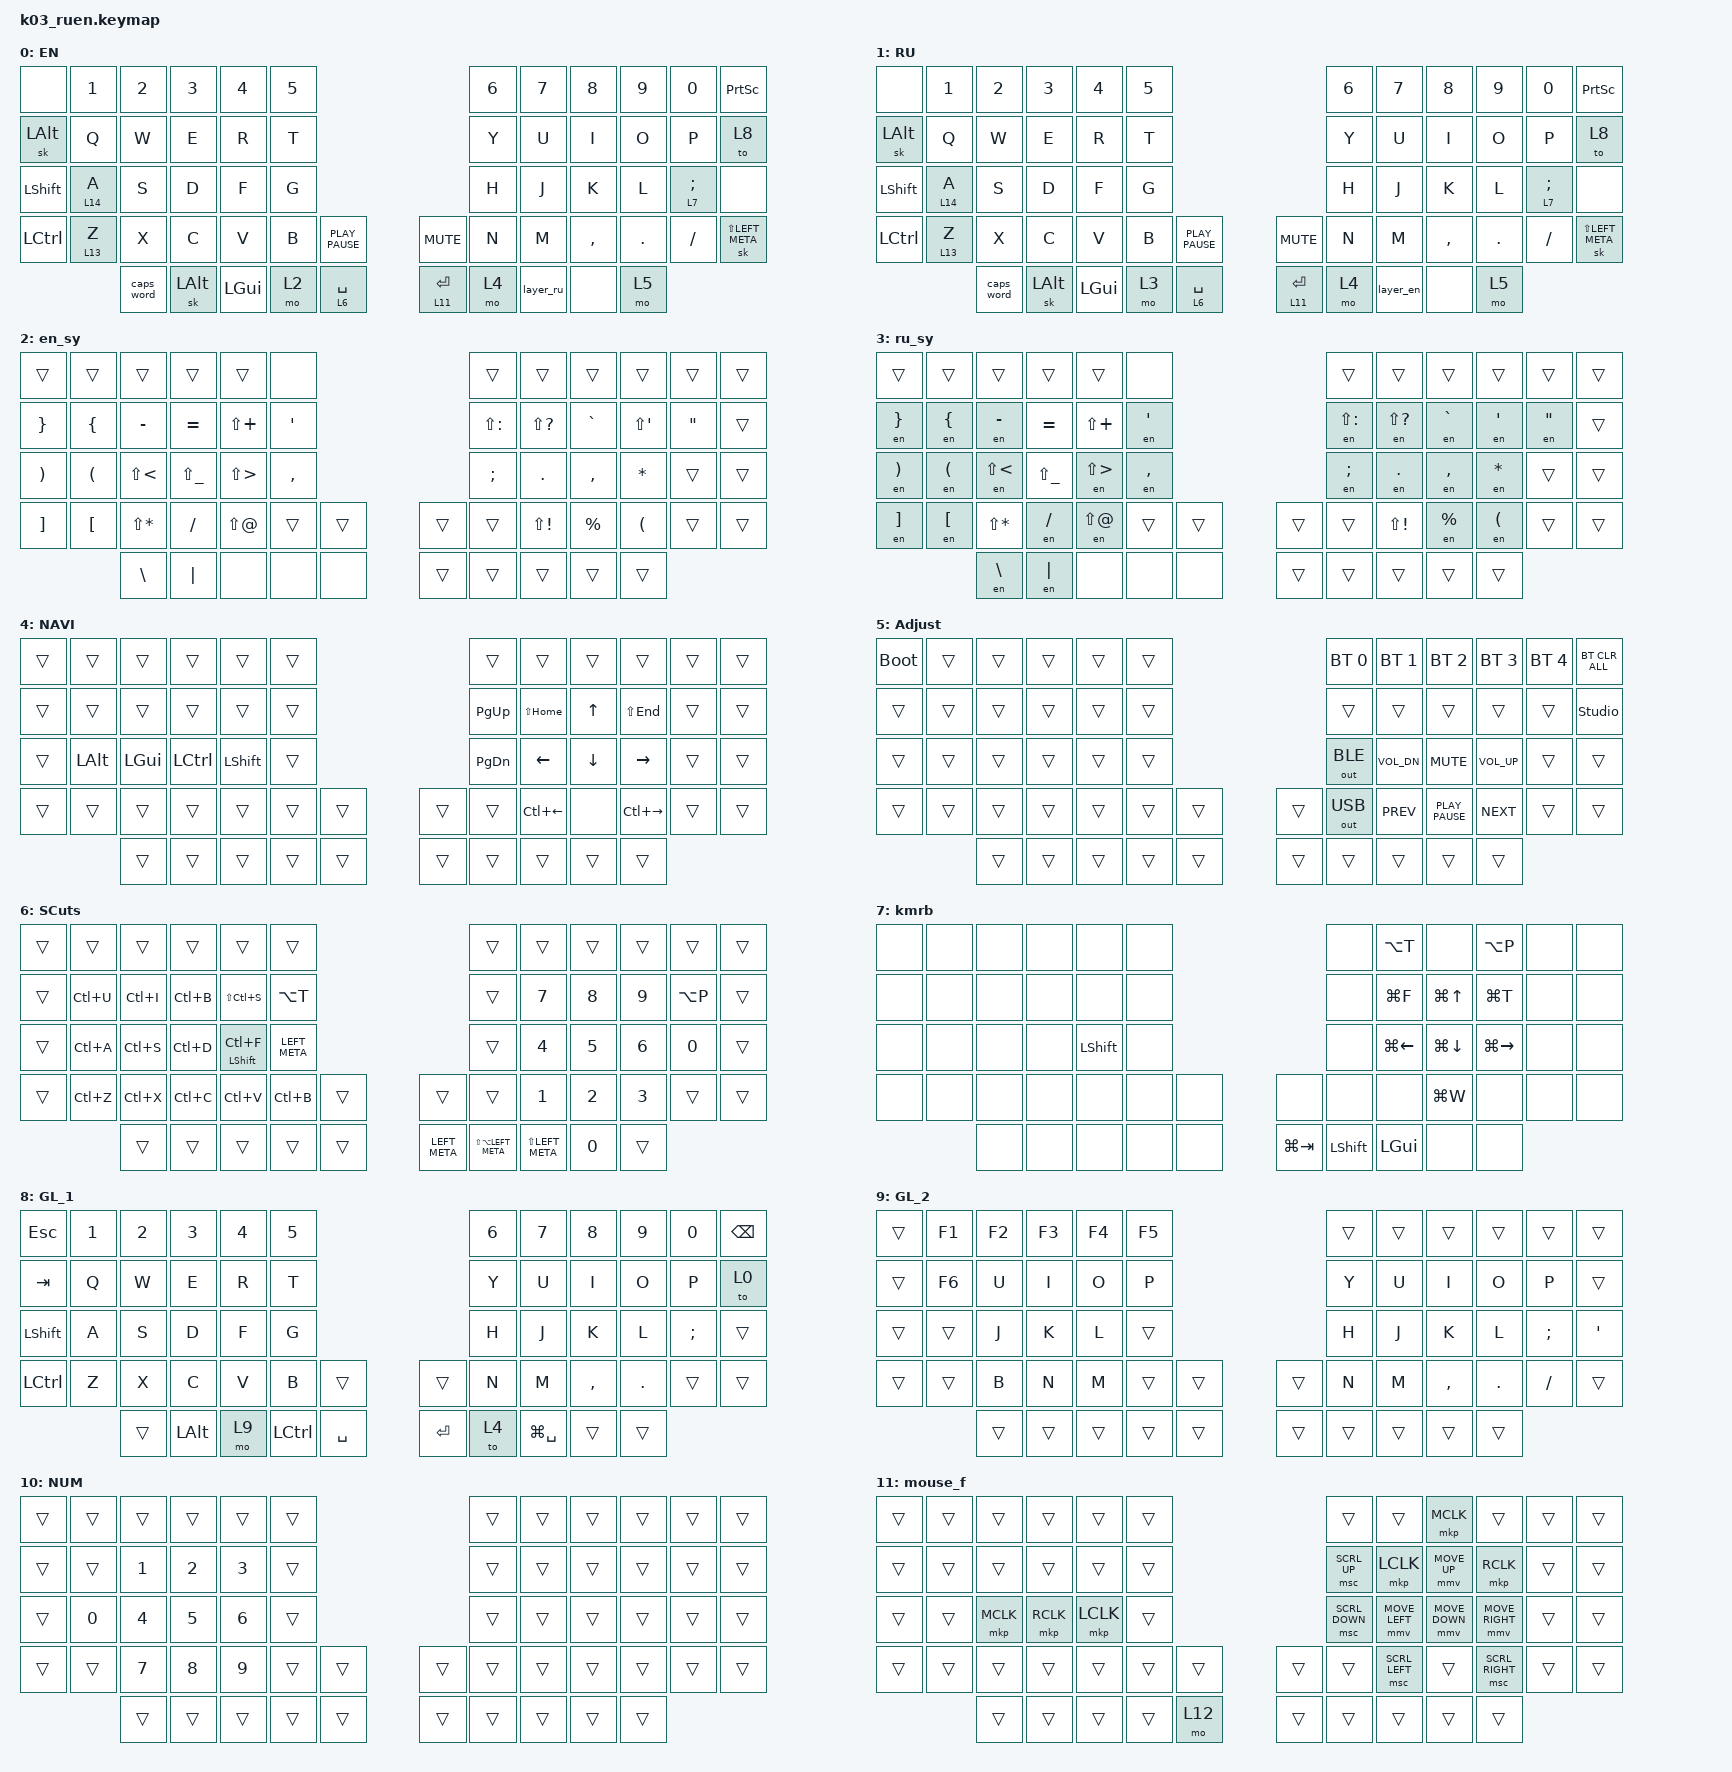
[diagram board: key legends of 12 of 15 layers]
#define ZMK_POINTING_DEFAULT_MOVE_VAL 1200
#define ZMK_POINTING_DEFAULT_SCRL_VAL 20

#include "keys_ru.h"
#include <input/processors.dtsi>
#include <behaviors.dtsi>
#include <dt-bindings/zmk/bt.h>
#include <dt-bindings/zmk/keys.h>
#include <dt-bindings/zmk/outputs.h>
#include <dt-bindings/zmk/pointing.h>

&mmv {
    time-to-max-speed-ms = <150>;
    acceleration-exponent = <1>;
};

&lt { tapping-term-ms = <185>; };

&mmv_input_listener {
    sniper {
        input-processors = <&zip_xy_scaler 1 6>;
        layers = <12>;
    };
};

/ {
    behaviors {
        enc_vol: enc_vol {
            compatible = "zmk,behavior-sensor-rotate";
            label = "ENC_VOL";
            #sensor-binding-cells = <0>;
            bindings = <&kp C_VOL_UP>, <&kp C_VOL_DN>;
        };

        td0: td0 {
            compatible = "zmk,behavior-tap-dance";
            label = "TD0";
            #binding-cells = <0>;
            bindings = <&kp MINUS>, <&kp LC(SLASH)>;

            tapping-term-ms = <300>;
        };

        td2: td2 {
            compatible = "zmk,behavior-tap-dance";
            label = "TD2";
            #binding-cells = <0>;
            tapping-term-ms = <300>;
            bindings = <&kp LS(LA(LEFT_BRACKET))>, <&kp LS(LA(H))>;
        };

        td3: td3 {
            compatible = "zmk,behavior-tap-dance";
            label = "TD3";
            #binding-cells = <0>;
            bindings = <&kp LS(LA(RIGHT_BRACKET))>, <&kp LS(LA(L))>;

            tapping-term-ms = <300>;
        };

        td4: td4 {
            compatible = "zmk,behavior-tap-dance";
            label = "TD4";
            #binding-cells = <0>;
            bindings = <&kp MINUS>, <&kp LC(SLASH)>;

            tapping-term-ms = <300>;
        };

        screen_shot: screen_shot {
            compatible = "zmk,behavior-tap-dance";
            label = "SCREEN_SHOT";
            #binding-cells = <0>;
            bindings = <&kp LS(PRINTSCREEN)>, <&kp PRINTSCREEN>;

            tapping-term-ms = <300>;
        };

        l_tap_hold: l_tap_hold {
            compatible = "zmk,behavior-hold-tap";
            label = "L_TAP_HOLD";
            bindings = <&mo>, <&kp>;

            #binding-cells = <2>;
            tapping-term-ms = <175>;
        };

        copy_paste_tap_dance: copy_paste_tap_dance {
            compatible = "zmk,behavior-hold-tap";
            label = "COPY_PASTE_TAP_DANCE";
            bindings = <&kp>, <&kp>;

            #binding-cells = <2>;
            flavor = "tap-preferred";
            tapping-term-ms = <190>;
            hold-trigger-on-release;
        };

        hrm: hrm {
            compatible = "zmk,behavior-hold-tap";
            label = "HRM";
            bindings = <&kp>, <&kp>;

            #binding-cells = <2>;
            tapping-term-ms = <190>;
            flavor = "tap-preferred";
        };
    };

    combos {
        compatible = "zmk,combos";

        ent {
            bindings = <&kp ENTER>;
            key-positions = <31 32>;
            layers = <4 8>;
        };

        bspac {
            bindings = <&kp BACKSPACE>;
            key-positions = <32 33>;
            layers = <4 8>;
        };

        del {
            bindings = <&kp DELETE>;
            key-positions = <46 47>;
            layers = <4>;
        };

        all {
            bindings = <&kp LC(A)>;
            key-positions = <25 26>;
            layers = <2 3>;
        };

        x {
            bindings = <&kp LEFT_BRACKET>;
            key-positions = <40 41>;
            layers = <0 1>;
        };

        left_br {
            bindings = <&kp RIGHT_BRACKET>;
            key-positions = <44 45>;
            layers = <0 1>;
        };

        e {
            bindings = <&kp SQT>;
            key-positions = <20 21>;
            layers = <0 1>;
        };

        esc {
            bindings = <&kp ESC>;
            key-positions = <13 14>;
            layers = <0 1>;
        };

        ctrT {
            bindings = <&kp LC(T)>;
            key-positions = <17 16>;
            layers = <2 3>;
        };

        buffer {
            bindings = <&kp LC(LG(V))>;
            key-positions = <39 40>;
            layers = <2 3>;
        };

        compact {
            bindings = <&kp LA(LC(C))>;
            key-positions = <37 38>;
            layers = <2 3>;
        };

        left_enter {
            bindings = <&kp ENTER>;
            key-positions = <28 27>;
            layers = <2 3>;
        };

        left_backspace {
            bindings = <&kp BACKSPACE>;
            key-positions = <27 26>;
            layers = <2 3>;
        };

        left_del {
            bindings = <&kp DELETE>;
            key-positions = <38 39>;
            layers = <2 3>;
        };

        tab {
            bindings = <&kp TAB>;
            key-positions = <15 14>;
            layers = <0 1>;
        };

        caps_work {
            bindings = <&caps_word>;
            key-positions = <26 28>;
            layers = <0 1>;
        };

        tg_swtcher {
            bindings = <&tog 13>;
            key-positions = <24 25>;
            layers = <0 1 13>;
        };
    };

    macros {
        to_ru: to_ru {
            compatible = "zmk,behavior-macro";
            #binding-cells = <0>;
            bindings = <&kp LS(LC(NUMBER_8))>;
            label = "TO_RU";
            wait-ms = <0>;
            tap-ms = <30>;
        };

        to_en: to_en {
            compatible = "zmk,behavior-macro";
            #binding-cells = <0>;
            bindings = <&kp LS(LC(N9))>;
            label = "TO_EN";
            wait-ms = <0>;
            tap-ms = <30>;
        };

        layer_en: layer_en {
            compatible = "zmk,behavior-macro";
            #binding-cells = <0>;
            bindings = <&to 0 &to_en>;
            label = "LAYER_EN";
            wait-ms = <0>;
            tap-ms = <30>;
        };

        layer_ru: layer_ru {
            compatible = "zmk,behavior-macro";
            #binding-cells = <0>;
            bindings = <&to 1 &to_ru>;
            label = "LAYER_RU";
            tap-ms = <30>;
            wait-ms = <0>;
        };

        en: en {
            compatible = "zmk,behavior-macro-one-param";
            #binding-cells = <1>;
            bindings =
                <&to_en>,
                <&macro_press>,
                <&macro_param_1to1 &kp MACRO_PLACEHOLDER>,
                <&macro_pause_for_release>,
                <&macro_release>,
                <&macro_param_1to1 &kp MACRO_PLACEHOLDER>,
                <&macro_tap>,
                <&to_ru>;

            label = "EN";
            wait-ms = <0>;
            tap-ms = <30>;
        };
    };

    keymap {
        compatible = "zmk,keymap";

        EN {
            bindings = <
&none         &kp N1    &kp N2      &kp N3        &kp N4        &kp N5                                       &kp N6  &kp N7     &kp N8     &kp N9   &kp N0      &kp PRINTSCREEN
&sk LEFT_ALT  &kp Q     &kp W       &kp E         &kp R         &kp T                                        &kp Y   &kp U      &kp I      &kp O    &kp P       &to 8
&kp LSHFT     &lt 14 A  &kp S       &kp D         &kp F         &kp G                                        &kp H   &kp J      &kp K      &kp L    &lt 7 SEMI  &none
&kp LCTRL     &lt 13 Z  &kp X       &kp C         &kp V         &kp B   &kp K_PLAY_PAUSE       &kp C_MUTE    &kp N   &kp M      &kp COMMA  &kp DOT  &kp FSLH    &sk LS(LEFT_META)
                        &caps_word  &sk LEFT_ALT  &kp LEFT_GUI  &mo 2   &l_tap_hold 6 SPACE    &lt 11 ENTER  &mo 4   &layer_ru  &none      &mo 5
            >;

            display-name = "EN";
            sensor-bindings = <&inc_dec_kp K_NEXT K_PREV>, <&enc_vol>;

            label = "EN";
        };

        RU {
            label = "RU";
            display-name = "RU";
            bindings = <
&none         &kp N1    &kp N2      &kp N3        &kp N4        &kp N5                                       &kp N6  &kp N7     &kp N8     &kp N9   &kp N0      &kp PRINTSCREEN
&sk LEFT_ALT  &kp Q     &kp W       &kp E         &kp R         &kp T                                        &kp Y   &kp U      &kp I      &kp O    &kp P       &to 8
&kp LSHFT     &lt 14 A  &kp S       &kp D         &kp F         &kp G                                        &kp H   &kp J      &kp K      &kp L    &lt 7 SEMI  &none
&kp LCTRL     &lt 13 Z  &kp X       &kp C         &kp V         &kp B   &kp K_PLAY_PAUSE       &kp C_MUTE    &kp N   &kp M      &kp COMMA  &kp DOT  &kp FSLH    &sk LS(LEFT_META)
                        &caps_word  &sk LEFT_ALT  &kp LEFT_GUI  &mo 3   &l_tap_hold 6 SPACE    &lt 11 ENTER  &mo 4   &layer_en  &none      &mo 5
            >;

            sensor-bindings = <&inc_dec_kp K_NEXT K_PREV>, <&enc_vol>;
        };

        en_sy {
            bindings = <
&trans                 &trans                &trans         &trans         &trans        &none                        &trans         &trans         &trans     &trans                &trans   &trans
&kp RIGHT_BRACE        &kp LEFT_BRACE        &kp MINUS      &kp EQUAL      &kp LS(PLUS)  &kp SQT                      &kp LS(COLON)  &kp LS(QMARK)  &kp GRAVE  &kp LS(SQT)           &kp DQT  &trans
&kp RIGHT_PARENTHESIS  &kp LEFT_PARENTHESIS  &kp LS(LT)     &kp LS(UNDER)  &kp LS(GT)    &kp COMMA                    &kp SEMI       &kp DOT        &kp COMMA  &kp STAR              &trans   &trans
&kp RIGHT_BRACKET      &kp LEFT_BRACKET      &kp LS(STAR)   &kp FSLH       &kp LS(AT)    &trans     &trans    &trans  &trans         &kp LS(EXCL)   &kp PRCNT  &kp LEFT_PARENTHESIS  &trans   &trans
                                             &kp BACKSLASH  &kp PIPE       &none         &none      &none     &trans  &trans         &trans         &trans     &trans
            >;

            label = "en_sy";
        };

        ru_sy {
            bindings = <
&trans                 &trans            &trans         &trans         &trans        &none                        &trans         &trans         &trans     &trans                &trans   &trans
&en RIGHT_BRACE        &en LEFT_BRACE    &en MINUS      &kp EQUAL      &kp LS(PLUS)  &en SQT                      &en LS(COLON)  &en LS(QMARK)  &en GRAVE  &en SQT               &en DQT  &trans
&en RIGHT_PARENTHESIS  &en LPAR          &en LS(LT)     &kp LS(UNDER)  &en LS(GT)    &en COMMA                    &en SEMI       &en DOT        &en COMMA  &en STAR              &trans   &trans
&en RIGHT_BRACKET      &en LEFT_BRACKET  &kp LS(STAR)   &en FSLH       &en LS(AT)    &trans     &trans    &trans  &trans         &kp LS(EXCL)   &en PRCNT  &en LEFT_PARENTHESIS  &trans   &trans
                                         &en BACKSLASH  &en PIPE       &none         &none      &none     &trans  &trans         &trans         &trans     &trans
            >;

            label = "ru_sy";
        };

        NAVI {
            bindings = <
&trans  &trans    &trans    &trans            &trans          &trans                    &trans     &trans        &trans    &trans         &trans  &trans
&trans  &trans    &trans    &trans            &trans          &trans                    &kp PG_UP  &kp LS(HOME)  &kp UP    &kp LS(END)    &trans  &trans
&trans  &kp LALT  &kp LGUI  &kp LEFT_CONTROL  &kp LEFT_SHIFT  &trans                    &kp PG_DN  &kp LEFT      &kp DOWN  &kp RIGHT      &trans  &trans
&trans  &trans    &trans    &trans            &trans          &trans  &trans    &trans  &trans     &kp LC(LEFT)  &none     &kp LC(RIGHT)  &trans  &trans
                  &trans    &trans            &trans          &trans  &trans    &trans  &trans     &trans        &trans    &trans
            >;

            label = "NAVI";
        };

        adj {
            bindings = <
&bootloader  &trans  &trans  &trans  &trans  &trans                    &bt BT_SEL 0  &bt BT_SEL 1  &bt BT_SEL 2      &bt BT_SEL 3  &bt BT_SEL 4  &bt BT_CLR_ALL
&trans       &trans  &trans  &trans  &trans  &trans                    &trans        &trans        &trans            &trans        &trans        &studio_unlock
&trans       &trans  &trans  &trans  &trans  &trans                    &out OUT_BLE  &kp C_VOL_DN  &kp K_MUTE        &kp C_VOL_UP  &trans        &trans
&trans       &trans  &trans  &trans  &trans  &trans  &trans    &trans  &out OUT_USB  &kp K_PREV    &kp K_PLAY_PAUSE  &kp K_NEXT    &trans        &trans
                     &trans  &trans  &trans  &trans  &trans    &trans  &trans        &trans        &trans            &trans
            >;

            display-name = "Adjust";
        };

        SCuts {
            bindings = <
&trans  &trans     &trans     &trans     &trans                &trans                                  &trans                 &trans             &trans  &trans  &trans     &trans
&trans  &kp LC(U)  &kp LC(I)  &kp LC(B)  &kp LS(LC(S))         &kp LA(T)                               &trans                 &kp N7             &kp N8  &kp N9  &kp LA(P)  &trans
&trans  &kp LC(A)  &kp LC(S)  &kp LC(D)  &mt LEFT_SHIFT LC(F)  &kp LEFT_META                           &trans                 &kp N4             &kp N5  &kp N6  &kp N0     &trans
&trans  &kp LC(Z)  &kp LC(X)  &kp LC(C)  &kp LC(V)             &kp LC(B)      &trans    &trans         &trans                 &kp N1             &kp N2  &kp N3  &trans     &trans
                   &trans     &trans     &trans                &trans         &trans    &kp LEFT_META  &kp LS(LA(LEFT_META))  &kp LS(LEFT_META)  &kp N0  &trans
            >;

            label = "SCuts";
        };

        kmrb {
            bindings = <
&none  &none  &none  &none  &none           &none                        &none      &kp LA(T)     &none         &kp LA(P)            &none  &none
&none  &none  &none  &none  &none           &none                        &none      &kp LG(F)     &kp LG(UP)    &kp LG(T)            &none  &none
&none  &none  &none  &none  &kp LEFT_SHIFT  &none                        &none      &kp LG(LEFT)  &kp LG(DOWN)  &kp LG(RIGHT_ARROW)  &none  &none
&none  &none  &none  &none  &none           &none  &none    &none        &none      &none         &kp LG(W)     &none                &none  &none
              &none  &none  &none           &none  &none    &kp LG(TAB)  &kp LSHFT  &kp LGUI      &none         &none
            >;

            label = "kmrb";
        };

        GL_1 {
            bindings = <
&kp ESC    &kp N1  &kp N2  &kp N3    &kp N4  &kp N5                             &kp N6  &kp N7         &kp N8     &kp N9   &kp N0    &kp BSPC
&kp TAB    &kp Q   &kp W   &kp E     &kp R   &kp T                              &kp Y   &kp U          &kp I      &kp O    &kp P     &to 0
&kp LSHFT  &kp A   &kp S   &kp D     &kp F   &kp G                              &kp H   &kp J          &kp K      &kp L    &kp SEMI  &trans
&kp LCTRL  &kp Z   &kp X   &kp C     &kp V   &kp B      &trans       &trans     &kp N   &kp M          &kp COMMA  &kp DOT  &trans    &trans
                   &trans  &kp LALT  &mo 9   &kp LCTRL  &kp SPACE    &kp ENTER  &to 4   &kp LG(SPACE)  &trans     &trans
            >;

            label = "GL_1";
            sensor-bindings = <&inc_dec_kp C_NEXT K_PREV>, <&enc_vol>;
        };

        GL_2 {
            bindings = <
&trans  &kp F1  &kp F2  &kp F3  &kp F4  &kp F5                    &trans  &trans  &trans     &trans   &trans    &trans
&trans  &kp F6  &kp U   &kp I   &kp O   &kp P                     &kp Y   &kp U   &kp I      &kp O    &kp P     &trans
&trans  &trans  &kp J   &kp K   &kp L   &trans                    &kp H   &kp J   &kp K      &kp L    &kp SEMI  &kp APOS
&trans  &trans  &kp B   &kp N   &kp M   &trans  &trans    &trans  &kp N   &kp M   &kp COMMA  &kp DOT  &kp FSLH  &trans
                &trans  &trans  &trans  &trans  &trans    &trans  &trans  &trans  &trans     &trans
            >;

            label = "GL_2";
        };

        NUM {
            bindings = <
&trans  &trans  &trans  &trans  &trans  &trans                    &trans  &trans  &trans  &trans  &trans  &trans
&trans  &trans  &kp N1  &kp N2  &kp N3  &trans                    &trans  &trans  &trans  &trans  &trans  &trans
&trans  &kp N0  &kp N4  &kp N5  &kp N6  &trans                    &trans  &trans  &trans  &trans  &trans  &trans
&trans  &trans  &kp N7  &kp N8  &kp N9  &trans  &trans    &trans  &trans  &trans  &trans  &trans  &trans  &trans
                &trans  &trans  &trans  &trans  &trans    &trans  &trans  &trans  &trans  &trans
            >;

            label = "NUM";
        };

        mouse_f {
            bindings = <
&trans  &trans  &trans     &trans     &trans     &trans                    &trans          &trans          &mkp MCLK       &trans           &trans  &trans
&trans  &trans  &trans     &trans     &trans     &trans                    &msc SCRL_UP    &mkp LCLK       &mmv MOVE_UP    &mkp RCLK        &trans  &trans
&trans  &trans  &mkp MCLK  &mkp RCLK  &mkp LCLK  &trans                    &msc SCRL_DOWN  &mmv MOVE_LEFT  &mmv MOVE_DOWN  &mmv MOVE_RIGHT  &trans  &trans
&trans  &trans  &trans     &trans     &trans     &trans  &trans    &trans  &trans          &msc SCRL_LEFT  &trans          &msc SCRL_RIGHT  &trans  &trans
                &trans     &trans     &trans     &trans  &mo 12    &trans  &trans          &trans          &trans          &trans
            >;

            label = "mouse_f";
        };

        mouse_s {
            bindings = <
&trans  &trans  &trans     &trans     &trans     &trans                    &trans          &trans          &mkp MCLK       &trans           &trans  &trans
&trans  &trans  &trans     &trans     &trans     &trans                    &msc SCRL_UP    &mkp LCLK       &mmv MOVE_UP    &mkp RCLK        &trans  &trans
&trans  &trans  &mkp MCLK  &mkp RCLK  &mkp LCLK  &trans                    &msc SCRL_DOWN  &mmv MOVE_LEFT  &mmv MOVE_DOWN  &mmv MOVE_RIGHT  &trans  &trans
&trans  &trans  &trans     &trans     &trans     &trans  &trans    &trans  &trans          &msc SCRL_LEFT  &trans          &msc SCRL_RIGHT  &trans  &trans
                &trans     &trans     &trans     &trans  &trans    &trans  &trans          &trans          &trans          &trans
            >;

            label = "mouse_s";
        };

        switcher {
            bindings = <
&trans  &trans  &trans       &trans       &trans       &trans                                    &trans          &trans          &mkp MB3  &trans           &trans  &trans
&trans  &trans  &mkp MB3     &mkp MB2     &mkp MB1     &msc SCRL_UP                              &msc SCRL_UP    &mkp LCLK       &trans    &mkp MB2         &trans  &trans
&trans  &trans  &kp LA(TAB)  &kp LC(TAB)  &kp LG(TAB)  &msc SCRL_DOWN                            &msc SCRL_DOWN  &trans          &trans    &trans           &trans  &trans
&trans  &trans  &kp LC(Q)    &kp LG(Q)    &kp LG(F)    &trans          &trans            &trans  &trans          &msc SCRL_LEFT  &trans    &msc SCRL_RIGHT  &trans  &trans
                &trans       &trans       &trans       &trans          &kp LEFT_SHIFT    &trans  &trans          &trans          &trans    &trans
            >;

            label = "switcher";
        };

        layer_14 {
            bindings = <
&trans  &trans  &trans          &trans          &trans           &trans                            &trans  &trans  &trans  &trans  &trans  &trans
&trans  &trans  &msc SCRL_LEFT  &msc SCRL_UP    &msc SCRL_RIGHT  &trans                            &trans  &trans  &trans  &trans  &trans  &trans
&trans  &trans  &mkp MB2        &msc SCRL_DOWN  &mkp MB1         &mkp MCLK                         &trans  &trans  &trans  &trans  &trans  &trans
&trans  &trans  &kp LC(Z)       &kp LC(C)       &kp LC(V)        &kp LS(LC(V))  &trans     &trans  &trans  &trans  &trans  &trans  &trans  &trans
                &trans          &trans          &trans           &kp BACKSPACE  &kp RET    &trans  &trans  &trans  &trans  &trans
            >;
        };
    };
};
